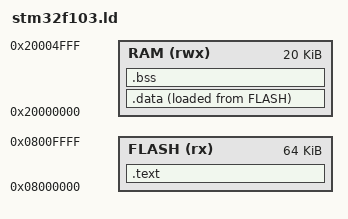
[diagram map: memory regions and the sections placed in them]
MEMORY
{
  FLASH (rx) : ORIGIN = 0x08000000, LENGTH = 64K
  RAM (rwx)  : ORIGIN = 0x20000000, LENGTH = 20K
}

ENTRY(reset_handler)

SECTIONS
{
  .text : {
    KEEP(*(.isr_vector))
    *(.text*)
    *(.rodata*)
  } > FLASH

  .data : {
    *(.data*)
  } > RAM AT > FLASH

  .bss : {
    *(.bss*)
    *(COMMON)
  } > RAM
}
